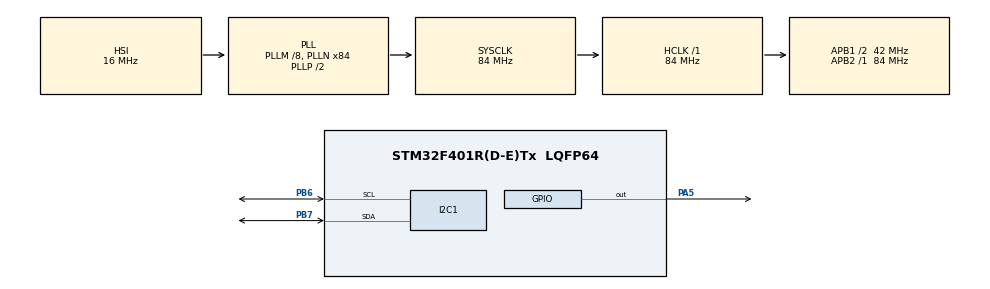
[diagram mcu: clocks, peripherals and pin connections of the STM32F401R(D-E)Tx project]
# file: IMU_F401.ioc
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Dma.I2C1_RX.0.Direction=DMA_PERIPH_TO_MEMORY
Dma.I2C1_RX.0.FIFOMode=DMA_FIFOMODE_DISABLE
Dma.I2C1_RX.0.Instance=DMA1_Stream0
Dma.I2C1_RX.0.MemDataAlignment=DMA_MDATAALIGN_BYTE
Dma.I2C1_RX.0.MemInc=DMA_MINC_ENABLE
Dma.I2C1_RX.0.Mode=DMA_NORMAL
Dma.I2C1_RX.0.PeriphDataAlignment=DMA_PDATAALIGN_BYTE
Dma.I2C1_RX.0.PeriphInc=DMA_PINC_DISABLE
Dma.I2C1_RX.0.Priority=DMA_PRIORITY_LOW
Dma.I2C1_TX.1.Direction=DMA_MEMORY_TO_PERIPH
Dma.I2C1_TX.1.FIFOMode=DMA_FIFOMODE_DISABLE
Dma.I2C1_TX.1.Instance=DMA1_Stream6
Dma.I2C1_TX.1.MemDataAlignment=DMA_MDATAALIGN_BYTE
Dma.I2C1_TX.1.MemInc=DMA_MINC_ENABLE
Dma.I2C1_TX.1.Mode=DMA_NORMAL
Dma.I2C1_TX.1.PeriphDataAlignment=DMA_PDATAALIGN_BYTE
Dma.I2C1_TX.1.PeriphInc=DMA_PINC_DISABLE
Dma.I2C1_TX.1.Priority=DMA_PRIORITY_LOW
Dma.Request0=I2C1_RX
Dma.Request1=I2C1_TX
I2C1.I2C_Mode=I2C_Fast
Mcu.Family=STM32F4
Mcu.Name=STM32F401R(D-E)Tx
Mcu.Package=LQFP64
NVIC.DMA1_Stream0_IRQn=true\:0\:0\:false\:false\:true\:false\:true\:true
NVIC.DMA1_Stream6_IRQn=true\:0\:0\:false\:false\:true\:false\:true\:true
NVIC.I2C1_ER_IRQn=true\:0\:0\:false\:false\:true\:true\:true\:true
NVIC.I2C1_EV_IRQn=true\:0\:0\:false\:false\:true\:true\:true\:true
NVIC.PriorityGroup=NVIC_PRIORITYGROUP_4
NVIC.TIM1_UP_TIM10_IRQn=true\:0\:0\:false\:false\:true\:true\:true\:true
PA13.Mode=Serial_Wire
PA13.Signal=SYS_JTMS-SWDIO
PA14.Mode=Serial_Wire
PA14.Signal=SYS_JTCK-SWCLK
PA5.Signal=GPIO_Output
PB6.GPIO_Pu=GPIO_PULLUP
PB6.Mode=I2C
PB6.Signal=I2C1_SCL
PB7.GPIO_Pu=GPIO_PULLUP
PB7.Mode=I2C
PB7.Signal=I2C1_SDA
PH0\ -\ OSC_IN.Mode=HSE-External-Oscillator
PH0\ -\ OSC_IN.Signal=RCC_OSC_IN
PH1\ -\ OSC_OUT.Mode=HSE-External-Oscillator
PH1\ -\ OSC_OUT.Signal=RCC_OSC_OUT
ProjectManager.HeapSize=0x200
ProjectManager.StackSize=0x400
ProjectManager.TargetToolchain=STM32CubeIDE
RCC.48MHZClocksFreq_Value=42000000
RCC.AHBFreq_Value=84000000
RCC.APB1CLKDivider=RCC_HCLK_DIV2
RCC.APB1Freq_Value=42000000
RCC.APB1TimFreq_Value=84000000
RCC.APB2Freq_Value=84000000
RCC.APB2TimFreq_Value=84000000
RCC.CortexFreq_Value=84000000
RCC.HCLKFreq_Value=84000000
RCC.HSE_VALUE=25000000
RCC.HSI_VALUE=16000000
RCC.LSE_VALUE=32768
RCC.PLLM=8
RCC.PLLN=84
RCC.SYSCLKFreq_VALUE=84000000
RCC.SYSCLKSource=RCC_SYSCLKSOURCE_PLLCLK
RCC.VCOOutputFreq_Value=168000000
TIM10.AutoReloadPreload=TIM_AUTORELOAD_PRELOAD_ENABLE
TIM10.Channel=TIM_CHANNEL_1
TIM10.OC1Preload=DISABLE
TIM10.Period=5000-1
TIM10.Prescaler=84-1
TIM10.Pulse=0
VP_TIM10_VS_ClockSourceINT.Mode=Enable_Timer
VP_TIM10_VS_no_output1.Mode=Output Compare1 No Output
board=custom

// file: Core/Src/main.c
/* USER CODE BEGIN Header */
/**
  ******************************************************************************
  * @file           : main.c
  * @brief          : Main program body
  ******************************************************************************
  * @attention
  *
  * Copyright (c) 2025 STMicroelectronics.
  * All rights reserved.
  *
  * This software is licensed under terms that can be found in the LICENSE file
  * in the root directory of this software component.
  * If no LICENSE file comes with this software, it is provided AS-IS.
  *
  ******************************************************************************
  */
/* USER CODE END Header */
#include "main.h"

I2C_HandleTypeDef hi2c1;
DMA_HandleTypeDef hdma_i2c1_rx;
DMA_HandleTypeDef hdma_i2c1_tx;

TIM_HandleTypeDef htim10;

/* USER CODE BEGIN PV */
ISM330DHCX ism = {0};
uint8_t buff = 249;
float dt = 0.005;

EulerAngles angle;

/* USER CODE END PV */

void SystemClock_Config(void);
static void MX_GPIO_Init(void);
static void MX_DMA_Init(void);
static void MX_I2C1_Init(void);
static void MX_TIM10_Init(void);

/* USER CODE BEGIN 0 */

// TIM overflow interrupt
void HAL_TIM_PeriodElapsedCallback(TIM_HandleTypeDef *htim){
	if(htim == &htim10){
		ISM_INTERRUPT_TIMER(&ism, dt);
	}
}

// DMA read interrupt
void HAL_I2C_MemRxCpltCallback(I2C_HandleTypeDef *hi2c){
	if(hi2c == &hi2c1){
		ISM_INTERRUPT_DMA(&ism);
	}
}

/* USER CODE END 0 */

int main(void)
{

  /* USER CODE BEGIN 1 */
	ISM330DHCX_Status status = ISM_NONE;
  /* USER CODE END 1 */

  /* MCU Configuration--------------------------------------------------------*/

  /* Reset of all peripherals, Initializes the Flash interface and the Systick. */
  HAL_Init();

  /* Configure the system clock */
  SystemClock_Config();

  /* USER CODE BEGIN SysInit */
  __reset_I2C1_LINE();
  /* USER CODE END SysInit */

  /* Initialize all configured peripherals */
  MX_GPIO_Init();
  MX_DMA_Init();
  MX_I2C1_Init();
  MX_TIM10_Init();
  /* USER CODE BEGIN 2 */

  status = init_ISM330DHCX(&ism, ISM_ADDRESS, &hi2c1);
  if(status != ISM_OK) Error_Handler();

  status = set_OutputDataRate_Accelerometer(&ism, ISM_ODR_416HZ);
  if(status != ISM_OK) Error_Handler();

  status = set_OutputDataRate_Gyroscope(&ism, ISM_ODR_416HZ);
  if(status != ISM_OK) Error_Handler();

  status = set_Fullscale_Accelerometer(&ism, ISM_FS_ACC_2G);
  if(status != ISM_OK) Error_Handler();

  status = set_Fullscale_Gyroscope(&ism, ISM_FS_GYRO_250);
  if(status != ISM_OK) Error_Handler();

  HAL_Delay(100);
  /* USER CODE END 2 */

  /* Infinite loop */
  /* USER CODE BEGIN WHILE */

  HAL_TIM_Base_Start_IT(&htim10);

  while (1)
  {
	  angle = quaternion_to_euler(ism.data.gyroscope.quaternion);
    /* USER CODE END WHILE */

  }
}

void SystemClock_Config(void)
{
  RCC_OscInitTypeDef RCC_OscInitStruct = {0};
  RCC_ClkInitTypeDef RCC_ClkInitStruct = {0};

  /** Configure the main internal regulator output voltage
  */
  __HAL_RCC_PWR_CLK_ENABLE();
  __HAL_PWR_VOLTAGESCALING_CONFIG(PWR_REGULATOR_VOLTAGE_SCALE2);

  /** Initializes the RCC Oscillators according to the specified parameters
  * in the RCC_OscInitTypeDef structure.
  */
  RCC_OscInitStruct.OscillatorType = RCC_OSCILLATORTYPE_HSI;
  RCC_OscInitStruct.HSIState = RCC_HSI_ON;
  RCC_OscInitStruct.HSICalibrationValue = RCC_HSICALIBRATION_DEFAULT;
  RCC_OscInitStruct.PLL.PLLState = RCC_PLL_ON;
  RCC_OscInitStruct.PLL.PLLSource = RCC_PLLSOURCE_HSI;
  RCC_OscInitStruct.PLL.PLLM = 8;
  RCC_OscInitStruct.PLL.PLLN = 84;
  RCC_OscInitStruct.PLL.PLLP = RCC_PLLP_DIV2;
  RCC_OscInitStruct.PLL.PLLQ = 4;
  if (HAL_RCC_OscConfig(&RCC_OscInitStruct) != HAL_OK)
  {
    Error_Handler();
  }

  /** Initializes the CPU, AHB and APB buses clocks
  */
  RCC_ClkInitStruct.ClockType = RCC_CLOCKTYPE_HCLK|RCC_CLOCKTYPE_SYSCLK
                              |RCC_CLOCKTYPE_PCLK1|RCC_CLOCKTYPE_PCLK2;
  RCC_ClkInitStruct.SYSCLKSource = RCC_SYSCLKSOURCE_PLLCLK;
  RCC_ClkInitStruct.AHBCLKDivider = RCC_SYSCLK_DIV1;
  RCC_ClkInitStruct.APB1CLKDivider = RCC_HCLK_DIV2;
  RCC_ClkInitStruct.APB2CLKDivider = RCC_HCLK_DIV1;

  if (HAL_RCC_ClockConfig(&RCC_ClkInitStruct, FLASH_LATENCY_2) != HAL_OK)
  {
    Error_Handler();
  }
}

static void MX_I2C1_Init(void)
{

  hi2c1.Instance = I2C1;
  hi2c1.Init.ClockSpeed = 400000;
  hi2c1.Init.DutyCycle = I2C_DUTYCYCLE_2;
  hi2c1.Init.OwnAddress1 = 0;
  hi2c1.Init.AddressingMode = I2C_ADDRESSINGMODE_7BIT;
  hi2c1.Init.DualAddressMode = I2C_DUALADDRESS_DISABLE;
  hi2c1.Init.OwnAddress2 = 0;
  hi2c1.Init.GeneralCallMode = I2C_GENERALCALL_DISABLE;
  hi2c1.Init.NoStretchMode = I2C_NOSTRETCH_DISABLE;
  if (HAL_I2C_Init(&hi2c1) != HAL_OK)
  {
    Error_Handler();
  }

}

static void MX_TIM10_Init(void)
{

  TIM_OC_InitTypeDef sConfigOC = {0};

  htim10.Instance = TIM10;
  htim10.Init.Prescaler = 84-1;
  htim10.Init.CounterMode = TIM_COUNTERMODE_UP;
  htim10.Init.Period = 5000-1;
  htim10.Init.ClockDivision = TIM_CLOCKDIVISION_DIV1;
  htim10.Init.AutoReloadPreload = TIM_AUTORELOAD_PRELOAD_ENABLE;
  if (HAL_TIM_Base_Init(&htim10) != HAL_OK)
  {
    Error_Handler();
  }
  if (HAL_TIM_OC_Init(&htim10) != HAL_OK)
  {
    Error_Handler();
  }
  sConfigOC.OCMode = TIM_OCMODE_TIMING;
  sConfigOC.Pulse = 0;
  sConfigOC.OCPolarity = TIM_OCPOLARITY_HIGH;
  sConfigOC.OCFastMode = TIM_OCFAST_DISABLE;
  if (HAL_TIM_OC_ConfigChannel(&htim10, &sConfigOC, TIM_CHANNEL_1) != HAL_OK)
  {
    Error_Handler();
  }

}

static void MX_DMA_Init(void)
{

  /* DMA controller clock enable */
  __HAL_RCC_DMA1_CLK_ENABLE();

  /* DMA interrupt init */
  /* DMA1_Stream0_IRQn interrupt configuration */
  HAL_NVIC_SetPriority(DMA1_Stream0_IRQn, 0, 0);
  HAL_NVIC_EnableIRQ(DMA1_Stream0_IRQn);
  /* DMA1_Stream6_IRQn interrupt configuration */
  HAL_NVIC_SetPriority(DMA1_Stream6_IRQn, 0, 0);
  HAL_NVIC_EnableIRQ(DMA1_Stream6_IRQn);

}

static void MX_GPIO_Init(void)
{
  GPIO_InitTypeDef GPIO_InitStruct = {0};

  /* GPIO Ports Clock Enable */
  __HAL_RCC_GPIOH_CLK_ENABLE();
  __HAL_RCC_GPIOA_CLK_ENABLE();
  __HAL_RCC_GPIOB_CLK_ENABLE();

  /*Configure GPIO pin Output Level */
  HAL_GPIO_WritePin(GPIOA, GPIO_PIN_5, GPIO_PIN_RESET);

  /*Configure GPIO pin : PA5 */
  GPIO_InitStruct.Pin = GPIO_PIN_5;
  GPIO_InitStruct.Mode = GPIO_MODE_OUTPUT_PP;
  GPIO_InitStruct.Pull = GPIO_NOPULL;
  GPIO_InitStruct.Speed = GPIO_SPEED_FREQ_LOW;
  HAL_GPIO_Init(GPIOA, &GPIO_InitStruct);

}

void Error_Handler(void)
{
  __disable_irq();
  while (1)
  {
  }
}
